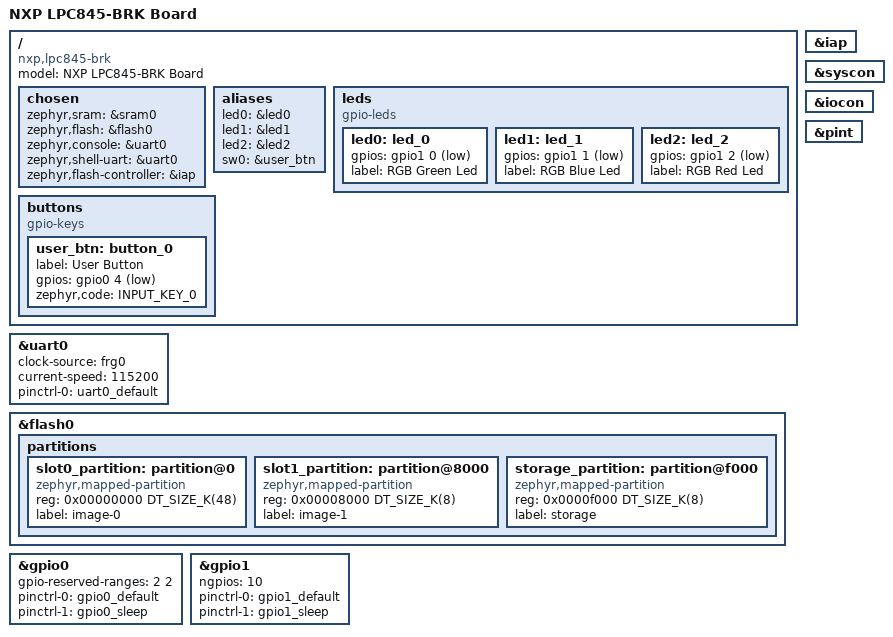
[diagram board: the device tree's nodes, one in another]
/*
 * Copyright (c) 2026 Aerlync Labs Inc.
 *
 * SPDX-License-Identifier: Apache-2.0
 */

/dts-v1/;

#include <nxp/lpc/lpc84x/nxp_lpc845.dtsi>
#include <zephyr/dt-bindings/gpio/gpio.h>
#include <zephyr/dt-bindings/input/input-event-codes.h>
#include "lpc845brk-pinctrl.dtsi"

/ {
	compatible = "nxp,lpc845-brk";
	model = "NXP LPC845-BRK Board";

	chosen {
		zephyr,sram = &sram0;
		zephyr,flash = &flash0;
		zephyr,console = &uart0;
		zephyr,shell-uart = &uart0;
		zephyr,flash-controller = &iap;
	};

	aliases {
		led0 = &led0;
		led1 = &led1;
		led2 = &led2;
		sw0 = &user_btn;
	};

	leds {
		compatible = "gpio-leds";

		led0: led_0 {
			gpios = <&gpio1 0 GPIO_ACTIVE_LOW>;
			label = "RGB Green Led";
		};

		led1: led_1 {
			gpios = <&gpio1 1 GPIO_ACTIVE_LOW>;
			label = "RGB Blue Led";
		};

		led2: led_2 {
			gpios = <&gpio1 2 GPIO_ACTIVE_LOW>;
			label = "RGB Red Led";
		};
	};

	buttons {
		compatible = "gpio-keys";

		user_btn: button_0 {
			label = "User Button";
			gpios = <&gpio0 4 (GPIO_PULL_UP | GPIO_ACTIVE_LOW)>;
			zephyr,code = <INPUT_KEY_0>;
		};
	};
};

&iap {
	status = "okay";
};

&syscon {
	status = "okay";
};

&iocon {
	status = "okay";
};

&uart0 {
	clock-source = "frg0";
	current-speed = <115200>;
	pinctrl-0 = <&uart0_default>;
	pinctrl-names = "default";
	status = "okay";
};

&flash0 {
	partitions {
		ranges;
		#address-cells = <1>;
		#size-cells = <1>;

		slot0_partition: partition@0 {
			compatible = "zephyr,mapped-partition";
			reg = <0x00000000 DT_SIZE_K(48)>;
			label = "image-0";
		};

		slot1_partition: partition@8000 {
			compatible = "zephyr,mapped-partition";
			reg = <0x00008000 DT_SIZE_K(8)>;
			label = "image-1";
		};

		storage_partition: partition@f000 {
			compatible = "zephyr,mapped-partition";
			reg = <0x0000f000 DT_SIZE_K(8)>;
			label = "storage";
		};
	};
};

&gpio0 {
	gpio-reserved-ranges = <2 2>;
	pinctrl-0 = <&gpio0_default>;
	pinctrl-1 = <&gpio0_sleep>;
	pinctrl-names = "default", "sleep";
	status = "okay";
};

&gpio1 {
	ngpios = <10>;
	pinctrl-0 = <&gpio1_default>;
	pinctrl-1 = <&gpio1_sleep>;
	pinctrl-names = "default", "sleep";
	status = "okay";
};

&pint {
	status = "okay";
};
